# R7FA6M3AH register map
Vendor: Renesas; Series: RA6; File version: 1.2
CPU: CM4 r0p1, little endian, MPU, FPU, VTOR, 4 interrupt priority bits
Registers are 32-bit, read-write, reset 0x0 unless marked. A register's access mark holds for its fields unless they carry their own. Offsets are from the block's base; [hi:lo] are bit positions.

## MMF — Memory Mirror Function
Base 0x40001000
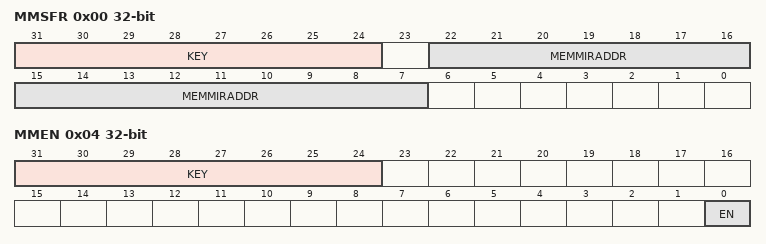
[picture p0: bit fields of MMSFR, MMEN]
0x00 MMSFR — MemMirror Special Function Register
  [31:24] KEY wo — MMSFR Key Code
  [22:7] MEMMIRADDR — Specifies the memory mirror address.NOTE: A value cannot be set in the low,order 7 bits. These bits are fixed to 0.
0x04 MMEN — MemMirror Enable Register
  [31:24] KEY wo — MMEN Key Code
  [0] EN — Memory Mirror Function Enable

## DMAC0 — Direct memory access controller 0
Base 0x40005000
Same registers: DMAC1 0x40005040, DMAC2 0x40005080, DMAC3 0x400050C0, DMAC4 0x40005100, DMAC5 0x40005140, DMAC6 0x40005180, DMAC7 0x400051C0
0x00 DMSAR — DMA Source Address Register
  [31:0] DMSAR — Specifies the transfer source start address.
0x04 DMDAR — DMA Destination Address Register
  [31:0] DMDAR — Specifies the transfer destination start address.
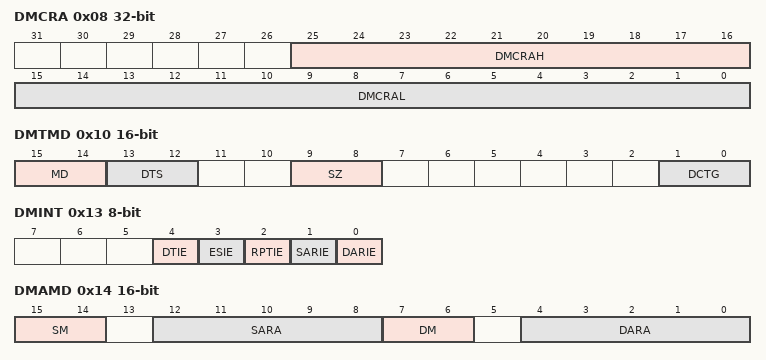
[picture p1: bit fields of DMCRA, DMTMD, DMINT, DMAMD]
0x08 DMCRA — DMA Transfer Count Register
  [25:16] DMCRAH — Upper bits of transfer count
  [15:0] DMCRAL — Lower bits of transfer count
0x0C DMCRB 16-bit — DMA Block Transfer Count Register
  [15:0] DMCRB — Specifies the number of block transfer operations or repeat transfer operations.
0x10 DMTMD 16-bit — DMA Transfer Mode Register
  [15:14] MD — Transfer Mode Select
  [13:12] DTS — Repeat Area Select
  [9:8] SZ — Transfer Data Size Select
  [1:0] DCTG — Transfer Request Source Select
0x13 DMINT 8-bit — DMA Interrupt Setting Register
  [4] DTIE — Transfer End Interrupt Enable
  [3] ESIE — Transfer Escape End Interrupt Enable
  [2] RPTIE — Repeat Size End Interrupt Enable
  [1] SARIE — Source Address Extended Repeat Area Overflow Interrupt Enable
  [0] DARIE — Destination Address Extended Repeat Area Overflow Interrupt Enable
0x14 DMAMD 16-bit — DMA Address Mode Register
  [15:14] SM — Source Address Update Mode
  [12:8] SARA — Source Address Extended Repeat Area Specifies the extended repeat area on the source address. For details on the settings.
  [7:6] DM — Destination Address Update Mode
  [4:0] DARA — Destination Address Extended Repeat Area Specifies the extended repeat area on the destination address. For details on the settings.
0x18 DMOFR — DMA Offset Register
  [31:0] DMOFR — Specifies the offset when offset addition is selected as the address update mode for transfer source or destination.
0x1C DMCNT 8-bit — DMA Transfer Enable Register
  [0] DTE read-modifies — DMA Transfer Enable
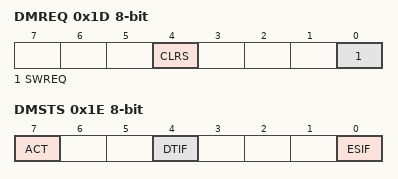
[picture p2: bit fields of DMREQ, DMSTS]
0x1D DMREQ 8-bit — DMA Software Start Register
  [4] CLRS — DMA Software Start Bit Auto Clear Select
  [0] SWREQ read-modifies — DMA Software Start
0x1E DMSTS 8-bit — DMAC Module Activation Register
  [7] ACT ro — DMA Active Flag
  [4] DTIF write-0-clears read-modifies — Transfer End Interrupt Flag
  [0] ESIF write-0-clears read-modifies — Transfer Escape End Interrupt Flag

## DMA — DMAC Module Activation
Base 0x40005200
0x00 DMAST 8-bit — DMA Module Activation Register
  [0] DMST — DMAC Operation Enable

## DTC — Data Transfer Controller
Base 0x40005400
0x00 DTCCR 8-bit reset 0x8 — DTC Control Register
  [4] RRS — DTC Transfer Information Read Skip Enable.
0x04 DTCVBR — DTC Vector Base Register
  [31:0] DTCVBR — DTC Vector Base Address.Note: A value cannot be set in the lower,order 10 bits. These bits are fixed to 0.
0x0C DTCST 8-bit — DTC Module Start Register
  [0] DTCST — DTC Module Start
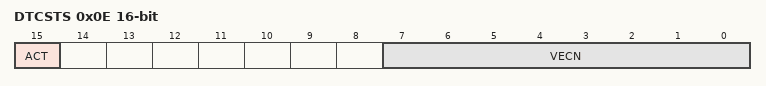
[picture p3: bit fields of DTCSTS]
0x0E DTCSTS 16-bit ro — DTC Status Register
  [15] ACT — DTC Active Flag
  [7:0] VECN — DTC,Activating Vector Number MonitoringThese bits indicate the vector number for the activating source when DTC transfer is in progress.The value is only valid if DTC transfer is in progress (the value of the ACT flag is 1)

## DBG — Debug Function
Base 0x4001B000
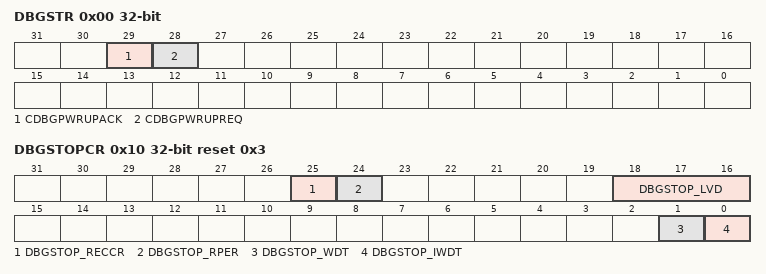
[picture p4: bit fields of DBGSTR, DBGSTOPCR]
0x00 DBGSTR ro — Debug Status Register
  [29] CDBGPWRUPACK — Debug power,up acknowledge
  [28] CDBGPWRUPREQ — Debug power,up request
0x10 DBGSTOPCR reset 0x3 — Debug Stop Control Register
  [25] DBGSTOP_RECCR — Mask bit for RAM ECC error reset/interrupt
  [24] DBGSTOP_RPER — Mask bit for RAM parity error reset/interrupt
  [18:16] DBGSTOP_LVD — b18: Mask bit for LVD2 reset/interrupt (0:enable / 1:Mask)b17: Mask bit for LVD1 reset/interrupt (0:enable / 1:Mask)b16: Mask bit for LVD0 reset (0:enable / 1:Mask)
  [1] DBGSTOP_WDT — Mask bit for WDT reset/interrupt
  [0] DBGSTOP_IWDT — Mask bit for IWDT reset/interrupt
0x20 TRACECTR — Trace Control Register
  [31] ENETBFULL — Enable bit for halt request by ETB full
